# AVR128DB28 register map
Vendor: Atmel; File version: 1.0
CPU: other r0p0, little endian, no MPU, no FPU, 4 interrupt priority bits
Registers are 8-bit, read-write, reset 0x0 unless marked. A register's access mark holds for its fields unless they carry their own. Offsets are from the block's base; [hi:lo] are bit positions.

## PORTMUX — Port Multiplexer
Base 0x008005E0
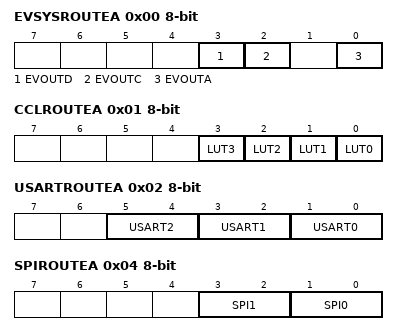
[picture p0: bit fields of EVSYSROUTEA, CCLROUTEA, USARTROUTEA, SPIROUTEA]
0x00 EVSYSROUTEA
  [3] EVOUTD — Event Output D
    0=DEFAULT (EVOUTD: PD2); 1=ALT1 (EVOUTD: PD7)
  [2] EVOUTC — Event Output C
    0=DEFAULT (EVOUTC: PC2)
  [0] EVOUTA — Event Output A
    0=DEFAULT (EVOUTA: PA2); 1=ALT1 (EVOUTA: PA7)
0x01 CCLROUTEA
  [3] LUT3 — CCL Look-Up Table 3 Signals
    0=DEFAULT (In: PF0, PF1, - Out: -)
  [2] LUT2 — CCL Look-Up Table 2 Signals
    0=DEFAULT (In: -, PD1, PD2 Out: PD3); 1=ALT1 (In: -, PD1, PD2 Out: PD6)
  [1] LUT1 — CCL Look-Up Table 1 Signals
    0=DEFAULT (In: PC0, PC1, PC2 Out: PC3); 1=ALT1 (In: PC0, PC1, PC2 Out: -)
  [0] LUT0 — CCL Look-Up Table 0 Signals
    0=DEFAULT (In: PA0, PA1, PA2 Out: PA3); 1=ALT1 (In: PA0, PA1, PA2 Out: PA6)
0x02 USARTROUTEA
  [5:4] USART2 — USART2 Signals
    0=DEFAULT (TxD: PF0, RxD: PF1, XCK: -, XDIR: -); 3=NONE (Not connected to any pins)
  [3:2] USART1 — USART1 Signals
    0=DEFAULT (TxD: PC0, RxD: PC1, XCK: PC2, XDIR: PC3); 3=NONE (Not connected to any pins)
  [1:0] USART0 — USART0 Signals
    0=DEFAULT (TxD: PA0, RxD: PA1, XCK: PA2, XDIR: PA3); 1=ALT1 (TxD: PA4, RxD: PA5, XCK: PA6, XDIR: PA7); 3=NONE (Not connected to any pins)
0x04 SPIROUTEA
  [3:2] SPI1 — SPI1 Signals
    0=DEFAULT (MOSI: PC0, MISO: PC1, SCK: PC2, SS: PC3); 3=NONE (Not connected to any pins)
  [1:0] SPI0 — SPI0 Signals
    0=DEFAULT (MOSI: PA4, MISO: PA5, SCK: PA6, SS: PA7); 3=NONE (Not connected to any pins)
0x05 TWIROUTEA
  [1:0] TWI0 — TWI0 Signals
    0=DEFAULT (SDA: PA2, SCL: PA3. Dual mode: SDA: PC2, SCL: PC3.); 1=ALT1 (SDA: PA2, SCL: PA3. Dual mode: SDA: -, SCL: -.); 2=ALT2 (SDA: PC2, SCL: PC3. Dual mode: SDA: -, SCL: -.)
0x06 TCAROUTEA
  [2:0] TCA0 — TCA0 Signals
    0=PORTA (WOn: PA0, PA1, PA2, PA3, PA4, PA5); 2=PORTC (WOn: PC0, PC1, PC2, PC3, -, -); 3=PORTD (WOn: -, PD1, PD2, PD3, PD4, PD5); 5=PORTF (WOn: PF0, PF1, -, -, -, -)
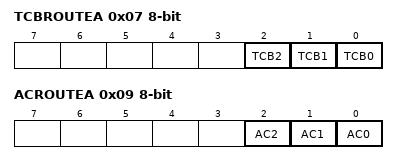
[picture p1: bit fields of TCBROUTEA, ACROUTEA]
0x07 TCBROUTEA
  [2] TCB2 — TCB2 Output
    0=DEFAULT (WO: PC0)
  [1] TCB1 — TCB1 Output
    0=DEFAULT (WO: PA3)
  [0] TCB0 — TCB0 Output
    0=DEFAULT (WO: PA2)
0x08 TCDROUTEA
  [2:0] TCD0 — TCD0 Signals
    0=DEFAULT (WOx: PA4, PA5, PA6, PA7); 2=ALT2 (WOx: PF0, PF1, -, -)
0x09 ACROUTEA
  [all] fields
    0=DEFAULT (OUT: PA7)
  [2] AC2 — Analog Comparator 2 Output
  [1] AC1 — Analog Comparator 1 Output
  [0] AC0 — Analog Comparator 0 Output
0x0A ZCDROUTEA
  [0] ZCD0 — Zero Cross Detector 0 Output
    0=DEFAULT (OUT: PA7)

## RSTCTRL — Reset controller
Base 0x00800040
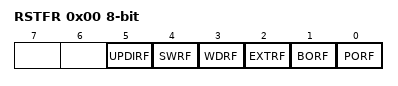
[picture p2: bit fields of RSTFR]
0x00 RSTFR — Reset Flags
  [5] UPDIRF — UPDI Reset flag
  [4] SWRF — Software Reset flag
  [3] WDRF — Watch dog Reset flag
  [2] EXTRF — External Reset flag
  [1] BORF — Brown out detector Reset flag
  [0] PORF — Power on Reset flag
0x01 SWRR — Software Reset
  [0] SWRST — Software reset enable

## RTC — Real-Time Counter
Base 0x00800140
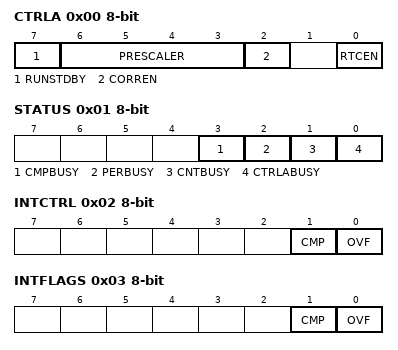
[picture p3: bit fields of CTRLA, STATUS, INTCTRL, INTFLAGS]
0x00 CTRLA — Control A
  [7] RUNSTDBY — Run In Standby
  [6:3] PRESCALER — Prescaling Factor
    0=DIV1 (RTC Clock / 1); 1=DIV2 (RTC Clock / 2); 2=DIV4 (RTC Clock / 4); 3=DIV8 (RTC Clock / 8); 4=DIV16 (RTC Clock / 16); 5=DIV32 (RTC Clock / 32); 6=DIV64 (RTC Clock / 64); 7=DIV128 (RTC Clock / 128); 8=DIV256 (RTC Clock / 256); 9=DIV512 (RTC Clock / 512); 10=DIV1024 (RTC Clock / 1024); 11=DIV2048 (RTC Clock / 2048); 12=DIV4096 (RTC Clock / 4096); 13=DIV8192 (RTC Clock / 8192); 14=DIV16384 (RTC Clock / 16384); 15=DIV32768 (RTC Clock / 32768)
  [2] CORREN — Correction enable
  [0] RTCEN — Enable
0x01 STATUS ro
  [3] CMPBUSY — Comparator Synchronization Busy Flag
  [2] PERBUSY — Period Synchronization Busy Flag
  [1] CNTBUSY — Count Synchronization Busy Flag
  [0] CTRLABUSY — CTRLA Synchronization Busy Flag
0x02 INTCTRL — Interrupt Control
  [1] CMP — Compare Match Interrupt enable
  [0] OVF — Overflow Interrupt enable
0x03 INTFLAGS — Interrupt Flags
  [1] CMP — Compare Match Interrupt
  [0] OVF — Overflow Interrupt Flag
0x04 TEMP — Temporary
0x05 DBGCTRL — Debug control
  [0] DBGRUN — Run in debug
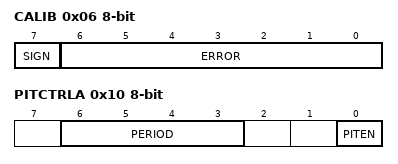
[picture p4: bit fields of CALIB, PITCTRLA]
0x06 CALIB — Calibration
  [7] SIGN — Error Correction Sign Bit
  [6:0] ERROR — Error Correction Value
0x07 CLKSEL — Clock Select
  [1:0] CLKSEL
    0=OSC32K (32.768 kHz from OSC32K); 1=OSC1K (1.024 kHz from OSC32K); 2=XOSC32K (32.768 kHz from XOSC32K); 3=EXTCLK (External Clock)
0x08 CNT 16-bit (reset mask 0xFF) — Counter
0x0A PER 16-bit (reset mask 0xFF) — Period
0x0C CMP 16-bit (reset mask 0xFF) — Compare
0x10 PITCTRLA — PIT Control A
  [6:3] PERIOD
    0=OFF; 1=CYC4 (RTC Clock Cycles 4); 2=CYC8 (RTC Clock Cycles 8); 3=CYC16 (RTC Clock Cycles 16); 4=CYC32 (RTC Clock Cycles 32); 5=CYC64 (RTC Clock Cycles 64); 6=CYC128 (RTC Clock Cycles 128); 7=CYC256 (RTC Clock Cycles 256); 8=CYC512 (RTC Clock Cycles 512); 9=CYC1024 (RTC Clock Cycles 1024); 10=CYC2048 (RTC Clock Cycles 2048); 11=CYC4096 (RTC Clock Cycles 4096); 12=CYC8192 (RTC Clock Cycles 8192); 13=CYC16384 (RTC Clock Cycles 16384); 14=CYC32768 (RTC Clock Cycles 32768)
  [0] PITEN — Enable
0x11 PITSTATUS ro
  [0] CTRLBUSY — CTRLA Synchronization Busy Flag
0x12 PITINTCTRL — PIT Interrupt Control
  [0] PI — Periodic Interrupt
0x13 PITINTFLAGS — PIT Interrupt Flags
  [0] PI — Periodic Interrupt
0x15 PITDBGCTRL — PIT Debug control
  [0] DBGRUN — Run in debug
